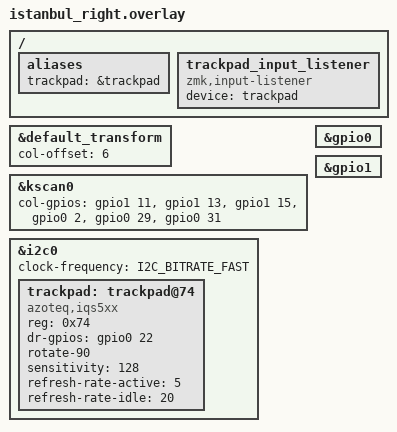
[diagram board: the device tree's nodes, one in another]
/*
 * Copyright (c) 2025 The ZMK Contributors
 *
 * SPDX-License-Identifier: MIT
 */


#include "istanbul.dtsi"

/ {
    aliases {
        trackpad = &trackpad;
    };

    // Input listener
    trackpad_input_listener: trackpad_input_listener {
        compatible = "zmk,input-listener";
        device = <&trackpad>;
        status = "okay";
    };
};


&default_transform {
    col-offset = <6>;
};

&kscan0 {
    col-gpios
        = <&gpio1 11 GPIO_ACTIVE_HIGH>  // col7
        , <&gpio1 13 GPIO_ACTIVE_HIGH>  // col8
        , <&gpio1 15 GPIO_ACTIVE_HIGH>  // col9
        , <&gpio0 2  GPIO_ACTIVE_HIGH>  // col10
        , <&gpio0 29 GPIO_ACTIVE_HIGH>  // col11
        , <&gpio0 31 GPIO_ACTIVE_HIGH>  // col12
        ;
};


// Enable GPIO controllers
&gpio0 {
    status = "okay";
};

&gpio1 {
    status = "okay";
};

&i2c0 {
    status = "okay";
    clock-frequency = <I2C_BITRATE_FAST>;

    trackpad: trackpad@74 {
        compatible = "azoteq,iqs5xx";
        reg = <0x74>;
        dr-gpios = <&gpio0 22 GPIO_ACTIVE_HIGH>;
        status = "okay";
        rotate-90;
        sensitivity = <128>;
        refresh-rate-active = <5>;
        refresh-rate-idle = <20>;
    };
};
